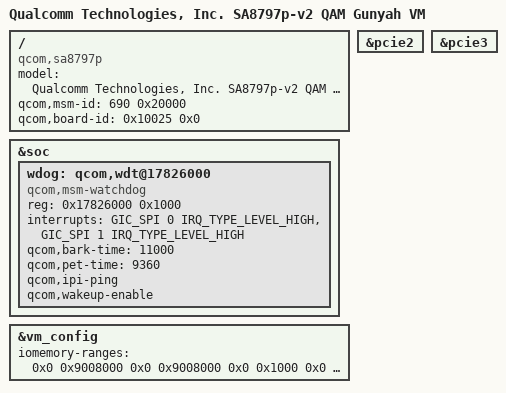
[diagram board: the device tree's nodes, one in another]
// SPDX-License-Identifier: BSD-3-Clause
/*
 * Copyright (c) Qualcomm Technologies, Inc. and/or its subsidiaries.
 */

/dts-v1/;

#include "sa8797p-gunyah-vm-qam.dtsi"

/ {
	model = "Qualcomm Technologies, Inc. SA8797p-v2 QAM Gunyah VM";
	compatible = "qcom,sa8797p", "qcom,qam";
	qcom,msm-id = <690 0x20000>;
	qcom,board-id = <0x10025 0x0>;
};

&soc {
	wdog: qcom,wdt@17826000 {
		compatible = "qcom,msm-watchdog";
		reg = <0x17826000 0x1000>;
		reg-names = "wdt-base";
		interrupts = <GIC_SPI 0 IRQ_TYPE_LEVEL_HIGH>,
			<GIC_SPI 1 IRQ_TYPE_LEVEL_HIGH>;
		qcom,bark-time = <11000>;
		qcom,pet-time = <9360>;
		qcom,ipi-ping;
		qcom,wakeup-enable;
	};
};

&pcie2 {
	ranges = <0x01000000 0x0 0x60000000 0x0 0x60000000 0x0 0x100000>,
		<0x02000000 0x0 0x60100000 0x0 0x60100000 0x0 0x7000000>,
		<0x43000000 0x40 0x10100000 0x40 0x10100000 0x0 0x100000>;
};

&pcie3 {
	ranges = <0x01000000 0x0 0x70000000 0x0 0x70000000 0x0 0x100000>,
		<0x02000000 0x0 0x70100000 0x0 0x70100000 0x0 0x7000000>,
		<0x43000000 0x4 0x10100000 0x4 0x10100000 0x0 0x100000>;
};

&vm_config {
	/* Pass through regions */
	iomemory-ranges = <
		/* MPROC NS1 IPCC region */
		0x0 0x9008000 0x0 0x9008000 0x0 0x1000 0x0
		/* QUPv3 Tile 2 read-only region */
		0x0 0x8C0000 0x0 0x8C0000 0x0 0x2000 0x1
		/* QUPv3 SE14 region */
		0x0 0x880000 0x0 0x880000 0x0 0x3000 0x0
		/* QUPv3 SE17 region */
		0x0 0x88C000 0x0 0x88C000 0x0 0x3000 0x0
		/* USB2 region */
		0x0 0x88e0000 0x0 0x88e0000 0x0 0x1000 0x0
		0x0 0xa200000 0x0 0xa200000 0x0 0x200000 0x0
		/* PCIE2 regions */
		0x40 0x0 0x40 0x0 0x0 0x10000000 0x0
		0x0 0x60000000 0x0 0x60000000 0x0 0x100000 0x0
		0x0 0x60100000 0x0 0x60100000 0x0 0x7000000 0x0
		0x40 0x10100000 0x40 0x10100000 0x0 0x100000 0x0
		/* TLMM region */
		0x0 0xF000000 0x0 0xF000000 0x0 0x1000000 0x0
		/* MDSS 0 region */
		0x0 0xAE00000 0x0 0xAE00000 0x0 0x180000 0x1
		/* MDSS 0 LUT DMA CTL region */
		0x0 0x0AF80000 0x0 0x0AF80000 0x0 0x1000 0x1
		/* MDSS 0 LUT DMA VQ region */
		0x0 0x0AF81000 0x0 0x0AF81000 0x0 0x10000 0x0
		/* MDSS 0 VA_TRAN CTL region */
		0x0 0xAFA4000 0x0 0xAFA4000 0x0 0x1000 0x1
		/* MDSS 0 VA_TRAN VQ region */
		0x0 0xAFA5000 0x0 0xAFA5000 0x0 0x10000 0x0
		/* MDSS 1 region */
		0x0 0x8C00000 0x0 0x8C00000 0x0 0x180000 0x1
		/* MDSS 1 LUT DMA CTL region */
		0x0 0x8D80000 0x0 0x8D80000 0x0 0x1000 0x1
		/* MDSS 1 LUT DMA VQ region */
		0x0 0x8D81000 0x0 0x8D81000 0x0 0x10000 0x0
		/* MDSS 1 VA_TRAN CTL region */
		0x0 0x8DA4000 0x0 0x8DA4000 0x0 0x1000 0x1
		/* MDSS 1 VA_TRAN VQ region */
		0x0 0x8DA5000 0x0 0x8DA5000 0x0 0x10000 0x0
		/* QRNG region */
		0x0 0x10cd000 0x0 0x10cd000 0x0 0x1000 0x0
		/* EMAC 1 DWC region */
		0x0 0x1A80000 0x0 0x1A80000 0x0 0x1A000 0x0
		/* EMAC 1 IO CSR region */
		0x0 0x1AFF000 0x0 0x1AFF000 0x0 0x1000 0x0
		/* GPU_0_GMU region */
		0x0 0x3D40000 0x0 0x3D40000 0x0 0x1000 0x0
		/* GPU_1_GMU region */
		0x0 0x9840000 0x0 0x9840000 0x0 0x1000 0x0
		/* PDC region */
		0x0 0xb220000 0x0 0xb220000 0x0 0x10000 0x0
		/* VCODEC CS1 region */
		0x0 0xAAA1000 0x0 0xAAA1000 0x0 0x1000 0x0
		/* USB1 region */
		0x0 0x88eb000 0x0 0x88eb000 0x0 0x1000 0x0
		0x0 0x88e4000 0x0 0x88e4000 0x0 0x3000 0x0
		0x0 0xa400000 0x0 0xa400000 0x0 0x200000 0x0
		/* PCIE3 regions */
		0x4 0x0 0x4 0x0 0x0 0x10000000 0x0
		0x0 0x70000000 0x0 0x70000000 0x0 0x100000 0x0
		0x0 0x70100000 0x0 0x70100000 0x0 0x7000000 0x0
		0x4 0x10100000 0x4 0x10100000 0x0 0x100000 0x0
		/* Fence NS1 IPCC region */
		0x0 0x9307000 0x0 0x9307000 0x0 0x1000 0x0
	>;
};
